VERSION ""

NS_ :

BS_:

BU_: TCU DIAG ECU HCU
VAL_TABLE_ Output_Fault 6 "No Voltage" 5 "Back Driven" 4 "Open Circuit" 3 "Over Current" 2 "Short Circuit" 1 "Okay ON" 0 "Okay OFF" ;
VAL_TABLE_ Analog_In_Fault 3 "Unknown" 2 "High Fault" 1 "Low Fault" 0 "Healthy" ;
VAL_TABLE_ Manual_Current_Command 3 "Unknown" 2 "Error" 1 "Manual Enable" 0 "Disable" ;

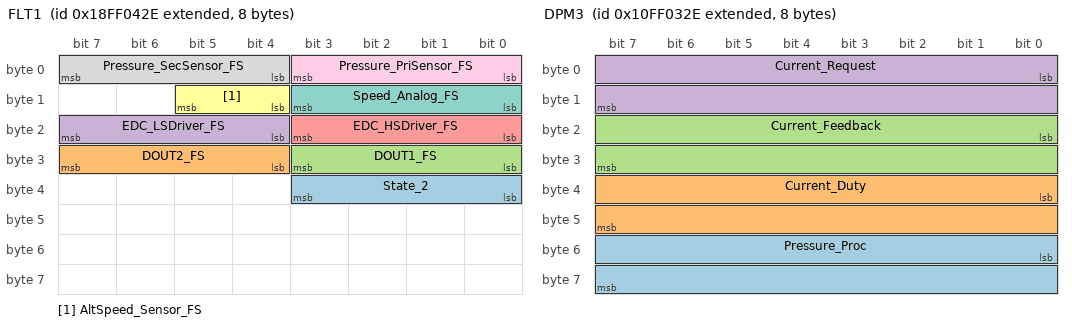
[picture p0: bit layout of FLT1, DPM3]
BO_ 2566849582 FLT1: 8 HCU
 SG_ State_2 : 32|4@1+ (1,0) [0|15] "" Vector__XXX
 SG_ DOUT2_FS : 28|4@1+ (1,0) [0|0] ""  DIAG
 SG_ DOUT1_FS : 24|4@1+ (1,0) [0|0] ""  DIAG
 SG_ EDC_LSDriver_FS : 20|4@1+ (1,0) [0|0] ""  DIAG
 SG_ EDC_HSDriver_FS : 16|4@1+ (1,0) [0|0] ""  DIAG
 SG_ AltSpeed_Sensor_FS : 12|2@1+ (1,0) [0|0] ""  DIAG
 SG_ Speed_Analog_FS : 8|4@1+ (1,0) [0|0] ""  DIAG
 SG_ Pressure_SecSensor_FS : 4|4@1+ (1,0) [0|0] ""  DIAG
 SG_ Pressure_PriSensor_FS : 0|4@1+ (1,0) [0|0] ""  DIAG

BO_ 2432631598 DPM3: 8 HCU
 SG_ Pressure_Proc : 48|16@1+ (0.1,0) [0|0] "bar"  DIAG
 SG_ Current_Duty : 32|16@1+ (0.1,0) [0|0] "%"  DIAG
 SG_ Current_Feedback : 16|16@1+ (1,0) [0|0] "mA"  DIAG
 SG_ Current_Request : 0|16@1+ (1,0) [0|0] "mA"  DIAG

BO_ 2566849273 DCM1: 8 DIAG
 SG_ Manual_Active : 16|8@1+ (1,0) [0|0] ""  HCU
 SG_ EDC_Current_Manual : 0|16@1+ (1,0) [0|0] "mA"  HCU

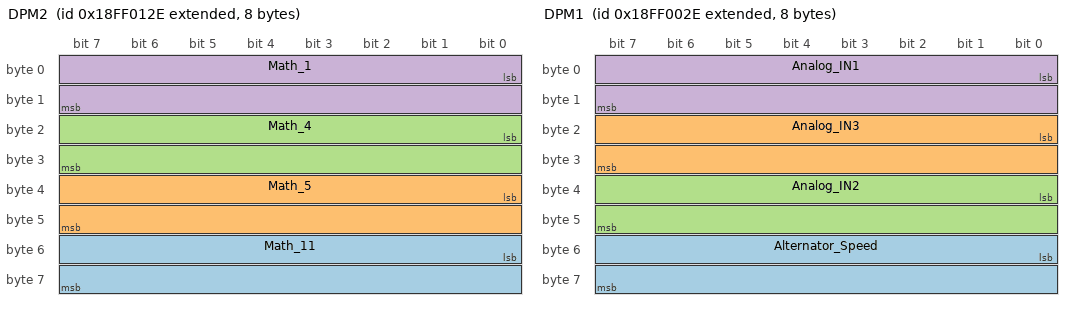
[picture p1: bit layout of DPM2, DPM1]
BO_ 2566848814 DPM2: 8 HCU
 SG_ Math_11 : 48|16@1+ (0.1,0) [0|0] "Nm"  DIAG,TCU
 SG_ Math_5 : 32|16@1+ (0.01,0) [0|0] "%"  DIAG
 SG_ Math_4 : 16|16@1+ (0.1,0) [0|0] "rpm"  DIAG
 SG_ Math_1 : 0|16@1+ (0.1,0) [0|0] "Nm"  DIAG

BO_ 2566848558 DPM1: 8 HCU
 SG_ Alternator_Speed : 48|16@1+ (1,0) [0|0] "rpm"  DIAG
 SG_ Analog_IN3 : 16|16@1+ (0.1,0) [0|0] "bar"  DIAG
 SG_ Analog_IN2 : 32|16@1+ (1,0) [0|0] "rpm"  DIAG
 SG_ Analog_IN1 : 0|16@1+ (0.1,0) [0|0] "bar"  DIAG

BO_ 2364539904 EEC1: 8 ECU
 SG_ Engine_Speed : 24|16@1+ (0.125,0) [0|0] "rpm"  HCU

CM_ BU_ TCU "Transmission Control Unit";
CM_ BU_ DIAG "Diagnostics Tool";
CM_ BU_ ECU "Engine Control Unit";
CM_ BU_ HCU "Hydraulics Control Unit";
CM_ BO_ 2566849582 "Diagnostic Faults & Parameters 1";
CM_ SG_ 2566849582 State_2 "STATE 2";
CM_ SG_ 2566849582 DOUT2_FS "DOUT2 - Fault Lamp - Fault Status PFW";
CM_ SG_ 2566849582 DOUT1_FS "DOUT1 - Relay Actualtion - Fault Status PFW";
CM_ SG_ 2566849582 EDC_LSDriver_FS "ECD Coil LS Driver - Fault Status PFW";
CM_ SG_ 2566849582 EDC_HSDriver_FS "ECD Coil HS Driver - Fault Status PFW";
CM_ SG_ 2566849582 AltSpeed_Sensor_FS "Alternator Speed Sensor Fault Status";
CM_ SG_ 2566849582 Speed_Analog_FS "Speed Analog Sensor Fault Status";
CM_ SG_ 2566849582 Pressure_SecSensor_FS "Pressure Secondary Sensor Fault Status";
CM_ SG_ 2566849582 Pressure_PriSensor_FS "Pressure Primary Sensor Fault Status";
CM_ BO_ 2432631598 "To Analyse Current Control at fast rate.
Later need to slow it down to 1000 ms";
CM_ SG_ 2432631598 Pressure_Proc "Processed Pressure Value";
CM_ SG_ 2432631598 Current_Duty "Duty Cycle for the Current control";
CM_ SG_ 2432631598 Current_Feedback "Feedback Current";
CM_ SG_ 2432631598 Current_Request "Requested Current to the PID loop";
CM_ BO_ 2566849273 "Diagnostics command message 1";
CM_ SG_ 2566849273 Manual_Active "Manual current command feature enable.";
CM_ SG_ 2566849273 EDC_Current_Manual "Manual command of EDC coil current.";
CM_ BO_ 2566848814 "Diagnostics Parameter Message 2";
CM_ SG_ 2566848814 Math_11 "Transmission Parameter";
CM_ SG_ 2566848814 Math_5 "Engine Slip";
CM_ SG_ 2566848814 Math_4 "Calculated Engine Speed";
CM_ SG_ 2566848814 Math_1 "Current Torque limit";
CM_ BO_ 2566848558 "Diagnostics Parameter Message 1";
CM_ SG_ 2566848558 Alternator_Speed "Alternator Speed";
CM_ SG_ 2566848558 Analog_IN3 "Pressure Sensor - Secondary";
CM_ SG_ 2566848558 Analog_IN2 "Speed Sensor - Analog";
CM_ SG_ 2566848558 Analog_IN1 "Pressure Sensor - Primary";
CM_ BO_ 2364539904 "Electronic Engine Controller 1";
CM_ SG_ 2364539904 Engine_Speed "Engine Speed";
BA_DEF_ SG_  "SigType" ENUM  "Default","Range","RangeSigned","ASCII","Discrete","Control","ReferencePGN","DTC","StringDelimiter","StringLength","StringLengthControl","MessageCounter","MessageChecksum";
BA_DEF_ SG_  "GenSigEVName" STRING ;
BA_DEF_ SG_  "GenSigILSupport" ENUM  "No","Yes";
BA_DEF_ SG_  "GenSigSendType" ENUM  "Cyclic","OnWrite","OnWriteWithRepetition","OnChange","OnChangeWithRepetition","IfActive","IfActiveWithRepetition","NoSigSendType";
BA_DEF_ BO_  "GenMsgILSupport" ENUM  "No","Yes";
BA_DEF_ BU_  "NmStationAddress" INT 0 255;
BA_DEF_ BO_  "GenMsgSendType" ENUM  "cyclic","NotUsed","IfActive","NotUsed","NotUsed","NotUsed","NotUsed","NotUsed","noMsgSendType";
BA_DEF_ BO_  "GenMsgRequestable" INT 0 1;
BA_DEF_ BO_  "GenMsgCycleTime" INT 0 3600000;
BA_DEF_ SG_  "SPN" INT 0 524287;
BA_DEF_  "DBName" STRING ;
BA_DEF_  "BusType" STRING ;
BA_DEF_ BO_  "VFrameFormat" ENUM  "StandardCAN","ExtendedCAN","reserved","PG";
BA_DEF_DEF_  "SigType" "Default";
BA_DEF_DEF_  "GenSigEVName" "Env@Nodename_@Signame";
BA_DEF_DEF_  "GenSigILSupport" "Yes";
BA_DEF_DEF_  "GenSigSendType" "NoSigSendType";
BA_DEF_DEF_  "GenMsgILSupport" "Yes";
BA_DEF_DEF_  "NmStationAddress" 254;
BA_DEF_DEF_  "GenMsgSendType" "noMsgSendType";
BA_DEF_DEF_  "GenMsgRequestable" 1;
BA_DEF_DEF_  "GenMsgCycleTime" 0;
BA_DEF_DEF_  "SPN" 0;
BA_DEF_DEF_  "DBName" "";
BA_DEF_DEF_  "BusType" "CAN";
BA_DEF_DEF_  "VFrameFormat" "PG";
BA_ "DBName" "_database";
BA_ "NmStationAddress" BU_ TCU 3;
BA_ "NmStationAddress" BU_ DIAG 249;
BA_ "NmStationAddress" BU_ ECU 0;
BA_ "NmStationAddress" BU_ HCU 46;
BA_ "GenMsgSendType" BO_ 2566849582 0;
BA_ "GenMsgCycleTime" BO_ 2566849582 1000;
BA_ "GenMsgSendType" BO_ 2432631598 0;
BA_ "GenMsgCycleTime" BO_ 2432631598 10;
BA_ "GenMsgSendType" BO_ 2566849273 2;
BA_ "GenMsgSendType" BO_ 2566848814 0;
BA_ "GenMsgCycleTime" BO_ 2566848814 1000;
BA_ "GenMsgCycleTime" BO_ 2566848558 1000;
BA_ "GenMsgSendType" BO_ 2566848558 0;
BA_ "GenMsgCycleTime" BO_ 2364539904 20;
BA_ "GenMsgSendType" BO_ 2364539904 0;
BA_ "SPN" SG_ 2566849582 State_2 520213;
BA_ "SPN" SG_ 2566849582 DOUT2_FS 520212;
BA_ "SPN" SG_ 2566849582 DOUT1_FS 520211;
BA_ "SPN" SG_ 2566849582 EDC_LSDriver_FS 520210;
BA_ "SPN" SG_ 2566849582 EDC_HSDriver_FS 520209;
BA_ "SPN" SG_ 2566849582 AltSpeed_Sensor_FS 520208;
BA_ "SPN" SG_ 2566849582 Speed_Analog_FS 520207;
BA_ "SPN" SG_ 2566849582 Pressure_SecSensor_FS 520206;
BA_ "SPN" SG_ 2566849582 Pressure_PriSensor_FS 520205;
BA_ "SPN" SG_ 2432631598 Pressure_Proc 520192;
BA_ "SPN" SG_ 2432631598 Current_Duty 520204;
BA_ "SPN" SG_ 2432631598 Current_Feedback 520203;
BA_ "SPN" SG_ 2432631598 Current_Request 520202;
BA_ "SPN" SG_ 2566849273 Manual_Active 520201;
BA_ "SPN" SG_ 2566849273 EDC_Current_Manual 520200;
BA_ "SPN" SG_ 2566848814 Math_11 520198;
BA_ "SPN" SG_ 2566848814 Math_5 520197;
BA_ "SPN" SG_ 2566848814 Math_4 520196;
BA_ "SPN" SG_ 2566848814 Math_1 520195;
BA_ "SPN" SG_ 2566848558 Alternator_Speed 520199;
BA_ "SPN" SG_ 2566848558 Analog_IN3 520193;
BA_ "SPN" SG_ 2566848558 Analog_IN2 520194;
BA_ "SPN" SG_ 2566848558 Analog_IN1 520192;
BA_ "SPN" SG_ 2364539904 Engine_Speed 1639;
VAL_ 2566849582 DOUT2_FS 6 "No Voltage" 5 "Back Driven" 4 "Open Circuit" 3 "Over Current" 2 "Short Circuit" 1 "Okay ON" 0 "Okay OFF" ;
VAL_ 2566849582 DOUT1_FS 6 "No Voltage" 5 "Back Driven" 4 "Open Circuit" 3 "Over Current" 2 "Short Circuit" 1 "Okay ON" 0 "Okay OFF" ;
VAL_ 2566849582 EDC_LSDriver_FS 6 "No Voltage" 5 "Back Driven" 4 "Open Circuit" 3 "Over Current" 2 "Short Circuit" 1 "Okay ON" 0 "Okay OFF" ;
VAL_ 2566849582 EDC_HSDriver_FS 6 "No Voltage" 5 "Back Driven" 4 "Open Circuit" 3 "Over Current" 2 "Short Circuit" 1 "Okay ON" 0 "Okay OFF" ;
VAL_ 2566849582 AltSpeed_Sensor_FS 3 "Unknown" 2 "Error" 1 "Faulty" 0 "Healthy" ;
VAL_ 2566849582 Speed_Analog_FS 3 "Unknown" 2 "High Fault" 1 "Low Fault" 0 "Healthy" ;
VAL_ 2566849582 Pressure_SecSensor_FS 3 "Unknown" 2 "High Fault" 1 "Low Fault" 0 "Healthy" ;
VAL_ 2566849582 Pressure_PriSensor_FS 3 "Unknown" 2 "High Fault" 1 "Low Fault" 0 "Healthy" ;
VAL_ 2566849273 Manual_Active 3 "Unknown" 2 "Error" 1 "Manual Enable" 0 "Disable" ;
